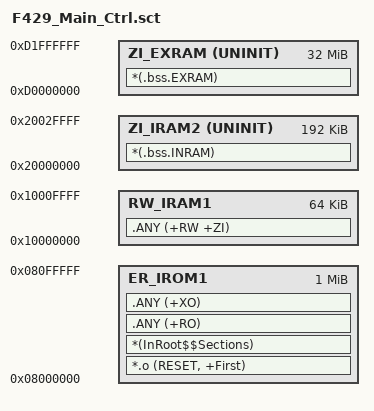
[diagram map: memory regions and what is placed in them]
; *************************************************************
; *** Scatter-Loading Description File generated by uVision ***
; *************************************************************

LR_IROM1 0x08000000 0x00100000  {    ; load region size_region
  ER_IROM1 0x08000000 0x00100000  {  ; load address = execution address
   *.o (RESET, +First)
   *(InRoot$$Sections)
   .ANY (+RO)
   .ANY (+XO)
  }
  RW_IRAM1 0x10000000 0x00010000  {  ; RW data
   .ANY (+RW +ZI)
  }
  ZI_IRAM2 0x20000000 UNINIT 0x00030000  {
   *(.bss.INRAM)
  }
  ZI_EXRAM 0xD0000000 UNINIT 0x02000000  {;不初始化内存，减少启动时间
   *(.bss.EXRAM)
  }
}

